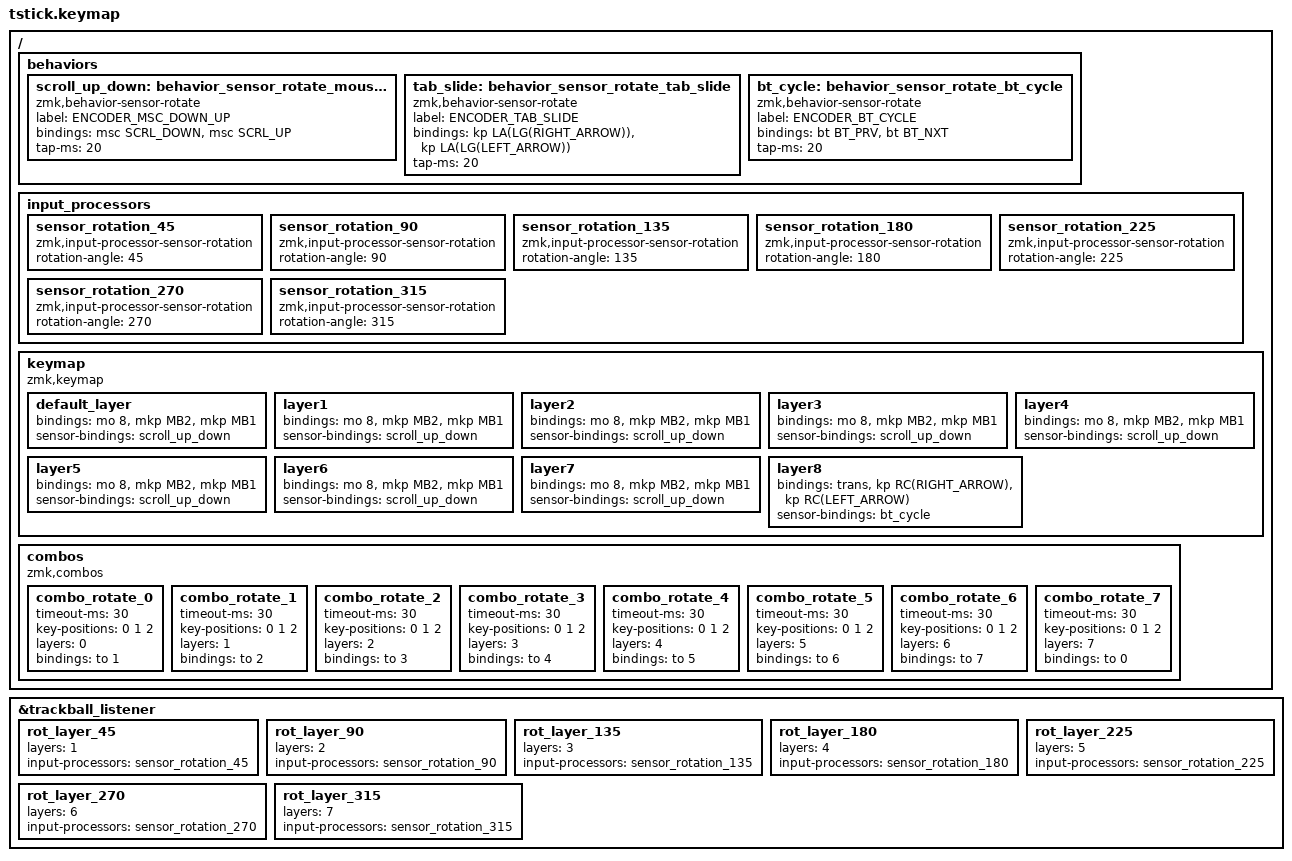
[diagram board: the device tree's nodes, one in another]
#include <behaviors.dtsi>
#include <dt-bindings/zmk/bt.h>
#include <dt-bindings/zmk/keys.h>
#include <dt-bindings/zmk/pointing.h>

#define ZMK_POINTING_DEFAULT_SCRL_VAL 80
/ {
    behaviors {
      scroll_up_down: behavior_sensor_rotate_mouse_wheel_up_down {
          compatible = "zmk,behavior-sensor-rotate";
          label = "ENCODER_MSC_DOWN_UP";
          #sensor-binding-cells = <0>;
          bindings = <&msc SCRL_DOWN>, <&msc SCRL_UP>;
          tap-ms = <20>;
      };

      tab_slide: behavior_sensor_rotate_tab_slide {
          compatible = "zmk,behavior-sensor-rotate";
          label = "ENCODER_TAB_SLIDE";
          #sensor-binding-cells = <0>;
          bindings = <&kp LA(LG(RIGHT_ARROW))>, <&kp LA(LG(LEFT_ARROW))>;
          tap-ms = <20>;
      };

      bt_cycle: behavior_sensor_rotate_bt_cycle {
          compatible = "zmk,behavior-sensor-rotate";
          label = "ENCODER_BT_CYCLE";
          #sensor-binding-cells = <0>;
          bindings = <&bt BT_PRV>, <&bt BT_NXT>;
          tap-ms = <20>;
      };
    };

    input_processors {
        sensor_rotation_45: sensor_rotation_45 {
            compatible = "zmk,input-processor-sensor-rotation";
            #input-processor-cells = <0>;
            rotation-angle = <45>;
        };

        sensor_rotation_90: sensor_rotation_90 {
            compatible = "zmk,input-processor-sensor-rotation";
            #input-processor-cells = <0>;
            rotation-angle = <90>;
        };

        sensor_rotation_135: sensor_rotation_135 {
            compatible = "zmk,input-processor-sensor-rotation";
            #input-processor-cells = <0>;
            rotation-angle = <135>;
        };

        sensor_rotation_180: sensor_rotation_180 {
            compatible = "zmk,input-processor-sensor-rotation";
            #input-processor-cells = <0>;
            rotation-angle = <180>;
        };

        sensor_rotation_225: sensor_rotation_225 {
            compatible = "zmk,input-processor-sensor-rotation";
            #input-processor-cells = <0>;
            rotation-angle = <225>;
        };

        sensor_rotation_270: sensor_rotation_270 {
            compatible = "zmk,input-processor-sensor-rotation";
            #input-processor-cells = <0>;
            rotation-angle = <270>;
        };

        sensor_rotation_315: sensor_rotation_315 {
            compatible = "zmk,input-processor-sensor-rotation";
            #input-processor-cells = <0>;
            rotation-angle = <315>;
        };
    };

    keymap {
        compatible = "zmk,keymap";

        default_layer {
            bindings = <
                &mo 8
                &mkp MB2
                &mkp MB1

            >;

            sensor-bindings = <&scroll_up_down>;
        };

        layer1 {
            bindings = <
                &mo 8
                &mkp MB2
                &mkp MB1
            >;

            sensor-bindings = <&scroll_up_down>;
        };

        layer2 {
            bindings = <
                &mo 8
                &mkp MB2
                &mkp MB1
            >;

            sensor-bindings = <&scroll_up_down>;
        };

        layer3 {
            bindings = <
                &mo 8
                &mkp MB2
                &mkp MB1
            >;

            sensor-bindings = <&scroll_up_down>;
        };

        layer4 {
            bindings = <
                &mo 8
                &mkp MB2
                &mkp MB1
            >;

            sensor-bindings = <&scroll_up_down>;
        };

        layer5 {
            bindings = <
                &mo 8
                &mkp MB2
                &mkp MB1
            >;

            sensor-bindings = <&scroll_up_down>;
        };

        layer6 {
            bindings = <
                &mo 8
                &mkp MB2
                &mkp MB1
            >;

            sensor-bindings = <&scroll_up_down>;
        };

        layer7 {
            bindings = <
                &mo 8
                &mkp MB2
                &mkp MB1
            >;

            sensor-bindings = <&scroll_up_down>;
        };

        layer8 {
            bindings = <
                &trans
                &kp RC(RIGHT_ARROW)
                &kp RC(LEFT_ARROW)
            >;

            sensor-bindings = <&bt_cycle>;
        };
    };

    combos {
        compatible = "zmk,combos";

        combo_rotate_0 {
            timeout-ms = <30>;
            key-positions = <0 1 2>;
            layers = <0>;
            bindings = <&to 1>;
        };

        combo_rotate_1 {
            timeout-ms = <30>;
            key-positions = <0 1 2>;
            layers = <1>;
            bindings = <&to 2>;
        };

        combo_rotate_2 {
            timeout-ms = <30>;
            key-positions = <0 1 2>;
            layers = <2>;
            bindings = <&to 3>;
        };

        combo_rotate_3 {
            timeout-ms = <30>;
            key-positions = <0 1 2>;
            layers = <3>;
            bindings = <&to 4>;
        };

        combo_rotate_4 {
            timeout-ms = <30>;
            key-positions = <0 1 2>;
            layers = <4>;
            bindings = <&to 5>;
        };

        combo_rotate_5 {
            timeout-ms = <30>;
            key-positions = <0 1 2>;
            layers = <5>;
            bindings = <&to 6>;
        };

        combo_rotate_6 {
            timeout-ms = <30>;
            key-positions = <0 1 2>;
            layers = <6>;
            bindings = <&to 7>;
        };

        combo_rotate_7 {
            timeout-ms = <30>;
            key-positions = <0 1 2>;
            layers = <7>;
            bindings = <&to 0>;
        };
    };
};

&trackball_listener {
    rot_layer_45 {
        layers = <1>;
        input-processors = <&sensor_rotation_45>;
    };

    rot_layer_90 {
        layers = <2>;
        input-processors = <&sensor_rotation_90>;
    };

    rot_layer_135 {
        layers = <3>;
        input-processors = <&sensor_rotation_135>;
    };

    rot_layer_180 {
        layers = <4>;
        input-processors = <&sensor_rotation_180>;
    };

    rot_layer_225 {
        layers = <5>;
        input-processors = <&sensor_rotation_225>;
    };

    rot_layer_270 {
        layers = <6>;
        input-processors = <&sensor_rotation_270>;
    };

    rot_layer_315 {
        layers = <7>;
        input-processors = <&sensor_rotation_315>;
    };
};
